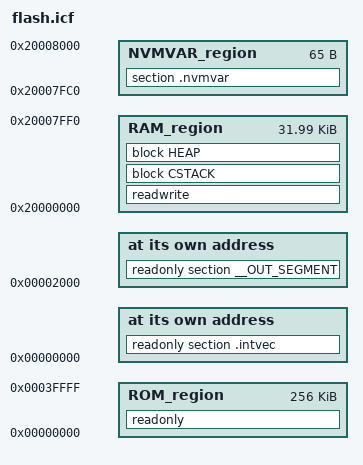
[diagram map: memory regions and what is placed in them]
/*###ICF### Section handled by ICF editor, don't touch! ****/
/*-Editor annotation file-*/
/* IcfEditorFile="$TOOLKIT_DIR$\config\ide\IcfEditor\cortex_v1_0.xml" */
/*-Specials-*/
define symbol __ICFEDIT_intvec_start__ = 0x0000000;
/*-Memory Regions-*/
define symbol __ICFEDIT_region_ROM_start__ = 0x00000000;
define symbol __ICFEDIT_region_ROM_end__   = 0x0003FFFF;
define symbol __ICFEDIT_region_RAM_start__ = 0x20000000;
define symbol __ICFEDIT_region_RAM_end__   = 0x20007FF0;

define symbol __ICFEDIT_region_NVM_BEFORELAST_PAGES_BEGIN__   = 0x00002000;
define symbol __ICFEDIT_region_NVM_BEFORELAST_PAGES_END__     = 0x00002ffF;
define symbol __ICFEDIT_region_NVM_LAST_PAGES_BEGIN__         = 0x2e00;
define symbol __ICFEDIT_region_NVM_LAST_PAGES_END__           = 0x2fff;

/*-Sizes-*/
define symbol __ICFEDIT_size_cstack__ = 0x1000;
define symbol __ICFEDIT_size_heap__   = 0x4000;
/**** End of ICF editor section. ###ICF###*/


define memory mem with size   = 4G ;
define region ROM_region   = mem:[from __ICFEDIT_region_ROM_start__   to __ICFEDIT_region_ROM_end__];
define region RAM_region   = mem:[from __ICFEDIT_region_RAM_start__   to __ICFEDIT_region_RAM_end__];

define block CSTACK    with alignment = 8, size = __ICFEDIT_size_cstack__ {} ;
define block HEAP      with alignment = 8, size = __ICFEDIT_size_heap__ {} ;

initialize by copy { readwrite };
//initialize by copy with packing = none { section __DLIB_PERTHREAD }; // Required in a multi-threaded application
do not initialize  { section .noinit };

place at address mem:__ICFEDIT_intvec_start__ { readonly section .intvec };


place at address mem:  __ICFEDIT_region_NVM_BEFORELAST_PAGES_BEGIN__ { readonly section  __OUT_SEGMENT };


place in ROM_region { readonly } ;
place in RAM_region   { readwrite,
                        block CSTACK, block HEAP };
                        
define region NVMVAR_region   = mem:[from 0x20007FC0   to 0x20008000 ];
do not initialize { section .nvmvar };
place in NVMVAR_region { section .nvmvar } ;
